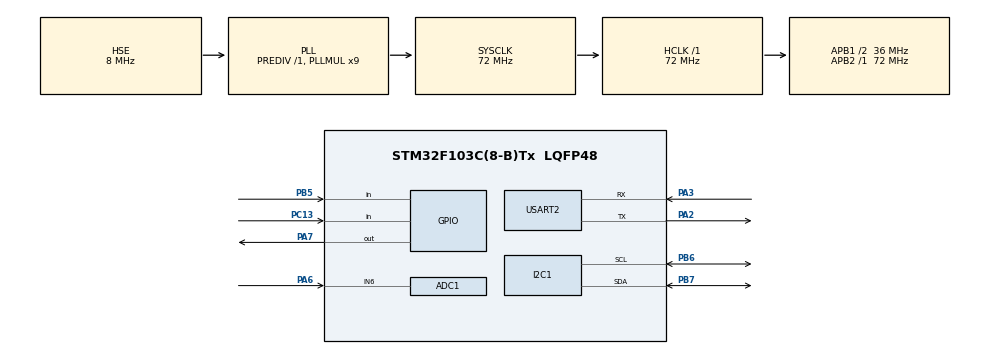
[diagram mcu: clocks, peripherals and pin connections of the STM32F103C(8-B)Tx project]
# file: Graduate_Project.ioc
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ADC1.Channel-6\#ChannelRegularConversion=ADC_CHANNEL_6
ADC1.NbrOfConversionFlag=1
ADC1.Rank-6\#ChannelRegularConversion=1
ADC1.SamplingTime-6\#ChannelRegularConversion=ADC_SAMPLETIME_1CYCLE_5
ADC1.master=1
Mcu.Family=STM32F1
Mcu.Name=STM32F103C(8-B)Tx
Mcu.Package=LQFP48
NVIC.PriorityGroup=NVIC_PRIORITYGROUP_4
NVIC.TIM2_IRQn=true\:0\:0\:false\:false\:true\:true\:true\:true
NVIC.USART2_IRQn=true\:0\:0\:false\:false\:true\:true\:true\:true
PA13.Mode=Serial_Wire
PA13.Signal=SYS_JTMS-SWDIO
PA14.Mode=Serial_Wire
PA14.Signal=SYS_JTCK-SWCLK
PA2.Mode=Asynchronous
PA2.Signal=USART2_TX
PA3.Mode=Asynchronous
PA3.Signal=USART2_RX
PA6.Signal=ADCx_IN6
PA7.Signal=GPIO_Output
PB5.Signal=GPIO_Input
PB6.Mode=I2C
PB6.Signal=I2C1_SCL
PB7.Mode=I2C
PB7.Signal=I2C1_SDA
PC13-TAMPER-RTC.GPIO_PuPd=GPIO_PULLUP
PC13-TAMPER-RTC.Signal=GPIO_Input
PD0-OSC_IN.Mode=HSE-External-Oscillator
PD0-OSC_IN.Signal=RCC_OSC_IN
PD1-OSC_OUT.Mode=HSE-External-Oscillator
PD1-OSC_OUT.Signal=RCC_OSC_OUT
ProjectManager.HeapSize=0x200
ProjectManager.StackSize=0x400
ProjectManager.TargetToolchain=STM32CubeIDE
RCC.ADCPresc=RCC_ADCPCLK2_DIV6
RCC.AHBFreq_Value=72000000
RCC.APB1CLKDivider=RCC_HCLK_DIV2
RCC.APB1Freq_Value=36000000
RCC.APB1TimFreq_Value=72000000
RCC.APB2Freq_Value=72000000
RCC.APB2TimFreq_Value=72000000
RCC.EnbaleCSS=true
RCC.HCLKFreq_Value=72000000
RCC.PLLMUL=RCC_PLL_MUL9
RCC.PLLSourceVirtual=RCC_PLLSOURCE_HSE
RCC.SYSCLKFreq_VALUE=72000000
RCC.SYSCLKSource=RCC_SYSCLKSOURCE_PLLCLK
RCC.USBFreq_Value=72000000
SH.ADCx_IN6.0=ADC1_IN6,IN6
TIM2.Period=9
TIM2.Prescaler=7199
USART2.VirtualMode=VM_ASYNC
VP_TIM2_VS_ClockSourceINT.Mode=Internal
board=custom

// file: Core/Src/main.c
/* USER CODE BEGIN Header */
/**
  * @file main.c
  * @brief CubeMX-managed STM32F103 BMS entry point.
  *
  * IMPORTANT: Keep application changes INSIDE USER CODE blocks.
  * Peripheral/clock configuration below is CubeMX-owned and should be
  * regenerated from the project's .ioc file.
  */
/* USER CODE END Header */
#include "main.h"

/* USER CODE BEGIN Includes */
#include "bms_app.h"
/* USER CODE END Includes */

ADC_HandleTypeDef hadc1;
I2C_HandleTypeDef hi2c1;
TIM_HandleTypeDef htim2;
UART_HandleTypeDef huart2;

void SystemClock_Config(void);
static void MX_GPIO_Init(void);
static void MX_I2C1_Init(void);
static void MX_ADC1_Init(void);
static void MX_USART2_UART_Init(void);
static void MX_TIM2_Init(void);

int main(void)
{

  HAL_Init();
  SystemClock_Config();

  MX_GPIO_Init();
  MX_I2C1_Init();
  MX_ADC1_Init();
  MX_USART2_UART_Init();
  MX_TIM2_Init();

  /* USER CODE BEGIN 2 */
  BMS_App_Init();
  /* USER CODE END 2 */

  while (1)
  {
    /* USER CODE BEGIN WHILE */
    BMS_App_Process();
    /* USER CODE END WHILE */

  }
}

/* The following functions are generated from CubeMX/.ioc. Do not put
 * BMS business logic into their bodies. This copy matches the prior
 * firmware only as an initial integration template. */
void SystemClock_Config(void) {
  RCC_OscInitTypeDef RCC_OscInitStruct = {0};
  RCC_ClkInitTypeDef RCC_ClkInitStruct = {0};
  RCC_PeriphCLKInitTypeDef PeriphClkInit = {0};

  RCC_OscInitStruct.OscillatorType = RCC_OSCILLATORTYPE_HSE;
  RCC_OscInitStruct.HSEState = RCC_HSE_ON;
  RCC_OscInitStruct.HSEPredivValue = RCC_HSE_PREDIV_DIV1;
  RCC_OscInitStruct.HSIState = RCC_HSI_ON;
  RCC_OscInitStruct.PLL.PLLState = RCC_PLL_ON;
  RCC_OscInitStruct.PLL.PLLSource = RCC_PLLSOURCE_HSE;
  RCC_OscInitStruct.PLL.PLLMUL = RCC_PLL_MUL9;
  HAL_RCC_OscConfig(&RCC_OscInitStruct);

  RCC_ClkInitStruct.ClockType = RCC_CLOCKTYPE_HCLK|RCC_CLOCKTYPE_SYSCLK|RCC_CLOCKTYPE_PCLK1|RCC_CLOCKTYPE_PCLK2;
  RCC_ClkInitStruct.SYSCLKSource = RCC_SYSCLKSOURCE_PLLCLK;
  RCC_ClkInitStruct.AHBCLKDivider = RCC_SYSCLK_DIV1;
  RCC_ClkInitStruct.APB1CLKDivider = RCC_HCLK_DIV2;
  RCC_ClkInitStruct.APB2CLKDivider = RCC_HCLK_DIV1;
  HAL_RCC_ClockConfig(&RCC_ClkInitStruct, FLASH_LATENCY_2);

  PeriphClkInit.PeriphClockSelection = RCC_PERIPHCLK_ADC;
  PeriphClkInit.AdcClockSelection = RCC_ADCPCLK2_DIV6;
  HAL_RCCEx_PeriphCLKConfig(&PeriphClkInit);
  HAL_RCC_EnableCSS();
}

static void MX_ADC1_Init(void) {
  ADC_ChannelConfTypeDef sConfig = {0};
  hadc1.Instance = ADC1;
  hadc1.Init.ScanConvMode = ADC_SCAN_DISABLE;
  hadc1.Init.ContinuousConvMode = DISABLE;
  hadc1.Init.DiscontinuousConvMode = DISABLE;
  hadc1.Init.ExternalTrigConv = ADC_SOFTWARE_START;
  hadc1.Init.DataAlign = ADC_DATAALIGN_RIGHT;
  hadc1.Init.NbrOfConversion = 1;
  HAL_ADC_Init(&hadc1);

  sConfig.Channel = ADC_CHANNEL_6;
  sConfig.Rank = ADC_REGULAR_RANK_1;
  sConfig.SamplingTime = ADC_SAMPLETIME_1CYCLE_5;
  HAL_ADC_ConfigChannel(&hadc1, &sConfig);
}

static void MX_I2C1_Init(void) {
  hi2c1.Instance = I2C1;
  hi2c1.Init.ClockSpeed = 100000;
  hi2c1.Init.DutyCycle = I2C_DUTYCYCLE_2;
  hi2c1.Init.OwnAddress1 = 0;
  hi2c1.Init.AddressingMode = I2C_ADDRESSINGMODE_7BIT;
  hi2c1.Init.DualAddressMode = I2C_DUALADDRESS_DISABLE;
  hi2c1.Init.OwnAddress2 = 0;
  hi2c1.Init.GeneralCallMode = I2C_GENERALCALL_DISABLE;
  hi2c1.Init.NoStretchMode = I2C_NOSTRETCH_DISABLE;
  HAL_I2C_Init(&hi2c1);
}

static void MX_TIM2_Init(void) {
  TIM_ClockConfigTypeDef sClockSourceConfig = {0};
  TIM_MasterConfigTypeDef sMasterConfig = {0};

  htim2.Instance = TIM2;
  htim2.Init.Prescaler = 7199;
  htim2.Init.CounterMode = TIM_COUNTERMODE_UP;
  htim2.Init.Period = 9;
  htim2.Init.ClockDivision = TIM_CLOCKDIVISION_DIV1;
  htim2.Init.AutoReloadPreload = TIM_AUTORELOAD_PRELOAD_DISABLE;
  HAL_TIM_Base_Init(&htim2);

  sClockSourceConfig.ClockSource = TIM_CLOCKSOURCE_INTERNAL;
  HAL_TIM_ConfigClockSource(&htim2, &sClockSourceConfig);

  sMasterConfig.MasterOutputTrigger = TIM_TRGO_RESET;
  sMasterConfig.MasterSlaveMode = TIM_MASTERSLAVEMODE_DISABLE;
  HAL_TIMEx_MasterConfigSynchronization(&htim2, &sMasterConfig);
}

static void MX_USART2_UART_Init(void) {
  huart2.Instance = USART2;
  huart2.Init.BaudRate = 115200;
  huart2.Init.WordLength = UART_WORDLENGTH_8B;
  huart2.Init.StopBits = UART_STOPBITS_1;
  huart2.Init.Parity = UART_PARITY_NONE;
  huart2.Init.Mode = UART_MODE_TX_RX;
  huart2.Init.HwFlowCtl = UART_HWCONTROL_NONE;
  huart2.Init.OverSampling = UART_OVERSAMPLING_16;
  HAL_UART_Init(&huart2);
}

static void MX_GPIO_Init(void) {
  GPIO_InitTypeDef GPIO_InitStruct = {0};

  __HAL_RCC_GPIOC_CLK_ENABLE();
  __HAL_RCC_GPIOD_CLK_ENABLE();
  __HAL_RCC_GPIOA_CLK_ENABLE();
  __HAL_RCC_GPIOB_CLK_ENABLE();

  /* Initialize PA7 load OFF and PC13 LED OFF before setting output modes.
   * Standard Blue Pill PC13 LED is active LOW. */
  HAL_GPIO_WritePin(GPIOA, GPIO_PIN_7, GPIO_PIN_RESET);
  HAL_GPIO_WritePin(GPIOC, GPIO_PIN_13, GPIO_PIN_SET);

  GPIO_InitStruct.Pin = GPIO_PIN_13;
  GPIO_InitStruct.Mode = GPIO_MODE_OUTPUT_PP;
  GPIO_InitStruct.Pull = GPIO_NOPULL;
  GPIO_InitStruct.Speed = GPIO_SPEED_FREQ_LOW;
  HAL_GPIO_Init(GPIOC, &GPIO_InitStruct);

  GPIO_InitStruct.Pin = GPIO_PIN_7;
  GPIO_InitStruct.Mode = GPIO_MODE_OUTPUT_PP;
  GPIO_InitStruct.Pull = GPIO_NOPULL;
  GPIO_InitStruct.Speed = GPIO_SPEED_FREQ_LOW;
  HAL_GPIO_Init(GPIOA, &GPIO_InitStruct);

  /* PB5 manual button: LOW when pressed, internal pull-up when released.
   * If your PCB already has a suitable external pull-up, this is redundant. */
  GPIO_InitStruct.Pin = GPIO_PIN_5;
  GPIO_InitStruct.Mode = GPIO_MODE_INPUT;
  GPIO_InitStruct.Pull = GPIO_PULLUP;
  HAL_GPIO_Init(GPIOB, &GPIO_InitStruct);

  /* Buttons 2..4 are not configured: their actual pins are not supplied. */
}

void Error_Handler(void)
{
  __disable_irq();
  while (1) { }
}

#ifdef USE_FULL_ASSERT
void assert_failed(uint8_t *file, uint32_t line)
{
  /* USER CODE BEGIN 6 */
  (void)file;
  (void)line;
  /* USER CODE END 6 */
}
#endif /* USE_FULL_ASSERT */
